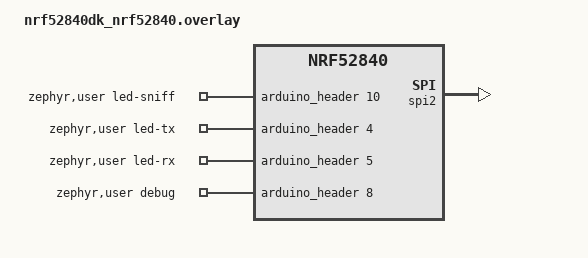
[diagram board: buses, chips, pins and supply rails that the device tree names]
/*
 * Copyright (c) 2024 Nordic Semiconductor ASA
 *
 * SPDX-License-Identifier: LicenseRef-Nordic-5-Clause
 */

/* It is a way to reassign the node label arduino_spi from spi2 to spi3.
 * spi2 draws way less current than spi3.
 */

/delete-node/ &arduino_spi;

arduino_spi: &spi2 {
    status = "okay";
    pinctrl-0 = <&spi3_default>;
    pinctrl-1 = <&spi3_sleep>;
    pinctrl-names = "default", "sleep";
};

/{
    zephyr,user {
        led-sniff-gpios = <&arduino_header 10 GPIO_ACTIVE_HIGH>;
        led-tx-gpios = <&arduino_header 4 GPIO_ACTIVE_HIGH>;
        led-rx-gpios = <&arduino_header 5 GPIO_ACTIVE_HIGH>;
        debug-gpios = <&arduino_header 8 GPIO_ACTIVE_HIGH>;
    };
};
